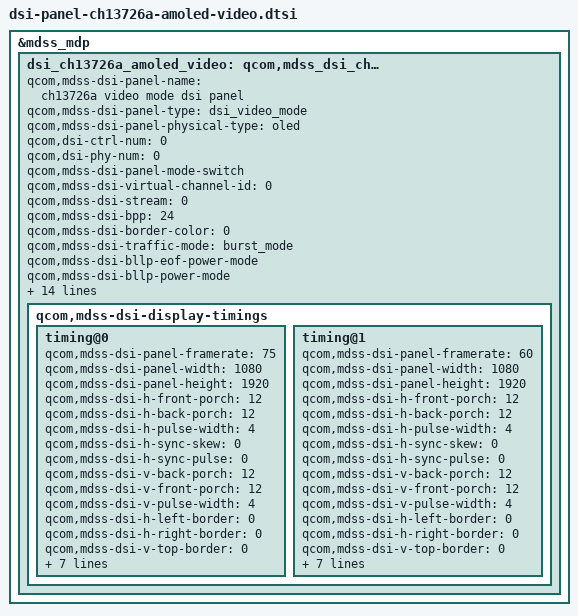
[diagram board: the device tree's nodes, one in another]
&mdss_mdp {
	dsi_ch13726a_amoled_video: qcom,mdss_dsi_ch13726a_amoled_video {
		qcom,mdss-dsi-panel-name = "ch13726a video mode dsi panel";
		qcom,mdss-dsi-panel-type = "dsi_video_mode";
		qcom,mdss-dsi-panel-physical-type = "oled";
		qcom,dsi-ctrl-num = <0>;
		qcom,dsi-phy-num = <0>;

		qcom,mdss-dsi-panel-mode-switch;
		qcom,mdss-dsi-virtual-channel-id = <0>;
		qcom,mdss-dsi-stream = <0>;
		qcom,mdss-dsi-bpp = <24>;
		qcom,mdss-dsi-border-color = <0>;

		qcom,mdss-dsi-traffic-mode = "burst_mode";
		qcom,mdss-dsi-bllp-eof-power-mode;
		qcom,mdss-dsi-bllp-power-mode;
		qcom,mdss-dsi-lane-0-state;
		qcom,mdss-dsi-lane-1-state;
		qcom,mdss-dsi-lane-2-state;
		qcom,mdss-dsi-lane-3-state;
		qcom,mdss-dsi-dma-trigger = "trigger_sw";
		qcom,mdss-dsi-mdp-trigger = "none";
		qcom,mdss-dsi-reset-sequence = <1 10>, <0 10>, <1 10>;
		qcom,adjust-timer-wakeup-ms = <1>;
		qcom,mdss-dsi-panel-hdr-enabled;
		qcom,mdss-dsi-panel-hdr-color-primaries = <14500 15500 32000
			17000 15500 30000 8000 3000>;
		qcom,mdss-dsi-panel-peak-brightness = <4200000>;
		qcom,mdss-dsi-panel-blackness-level = <3230>;
		qcom,mdss-dsi-panel-orientation = "180";

		qcom,mdss-dsi-display-timings {
			timing@0 {
				qcom,mdss-dsi-panel-framerate = <75>;
				qcom,mdss-dsi-panel-width = <1080>;
				qcom,mdss-dsi-panel-height = <1920>;
				qcom,mdss-dsi-h-front-porch = <12>;
				qcom,mdss-dsi-h-back-porch = <12>;
				qcom,mdss-dsi-h-pulse-width = <4>;
				qcom,mdss-dsi-h-sync-skew = <0>;
				qcom,mdss-dsi-h-sync-pulse = <0>;
				qcom,mdss-dsi-v-back-porch = <12>;
				qcom,mdss-dsi-v-front-porch = <12>;
				qcom,mdss-dsi-v-pulse-width = <4>;
				qcom,mdss-dsi-h-left-border = <0>;
				qcom,mdss-dsi-h-right-border = <0>;
				qcom,mdss-dsi-v-top-border = <0>;
				qcom,mdss-dsi-v-bottom-border = <0>;

				qcom,mdss-dsi-on-command = [
					39 01 00 00 00 00 02 F0 50
					39 01 00 00 00 00 02 B9 00 // Bypass GRAM
					05 01 00 00 78 00 02 11 00 // Sleep Out
					05 01 00 00 14 00 02 29 00 // Display On
				];
				qcom,mdss-dsi-on-command-state = "dsi_lp_mode";

				qcom,mdss-dsi-off-command = [
					05 01 00 00 32 00 02 28 00 // Display Off
					05 01 00 00 78 00 02 10 00 // Sleep In
				];
				qcom,mdss-dsi-off-command-state = "dsi_hs_mode";
			};

			timing@1 {
				qcom,mdss-dsi-panel-framerate = <60>;
				qcom,mdss-dsi-panel-width = <1080>;
				qcom,mdss-dsi-panel-height = <1920>;
				qcom,mdss-dsi-h-front-porch = <12>;
				qcom,mdss-dsi-h-back-porch = <12>;
				qcom,mdss-dsi-h-pulse-width = <4>;
				qcom,mdss-dsi-h-sync-skew = <0>;
				qcom,mdss-dsi-h-sync-pulse = <0>;
				qcom,mdss-dsi-v-back-porch = <12>;
				qcom,mdss-dsi-v-front-porch = <12>;
				qcom,mdss-dsi-v-pulse-width = <4>;
				qcom,mdss-dsi-h-left-border = <0>;
				qcom,mdss-dsi-h-right-border = <0>;
				qcom,mdss-dsi-v-top-border = <0>;
				qcom,mdss-dsi-v-bottom-border = <0>;

				qcom,mdss-dsi-on-command = [
					39 01 00 00 00 00 02 F0 50
					39 01 00 00 00 00 02 B9 00 // Bypass GRAM
					05 01 00 00 78 00 02 11 00 // Sleep Out
					05 01 00 00 14 00 02 29 00 // Display On
				];
				qcom,mdss-dsi-on-command-state = "dsi_lp_mode";

				qcom,mdss-dsi-off-command = [
					05 01 00 00 32 00 02 28 00 // Display Off
					05 01 00 00 78 00 02 10 00 // Sleep In
				];
				qcom,mdss-dsi-off-command-state = "dsi_hs_mode";
			};
		};
	};
};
